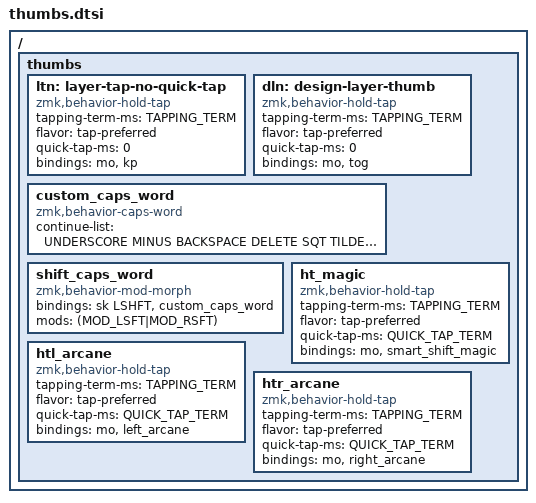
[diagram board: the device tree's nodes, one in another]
/*
*
* Copyright (c) 2022 Rafael Romão
* SPDX-License-Identifier: MIT
*
*/

/ {
    // #define SMART_REPEAT(NAME, LABEL, DEFAULT) \
    //     NAME: NAME { \
    //         compatible = "zmk,behavior-antecedent-morph"; \
    //         label = LABEL; \
    //         #binding-cells = <0>; \
    //         max-delay-ms = <ADAPTIVE_KEY_TIMEOUT>; \
    //         defaults = <DEFAULT>; \
    //         antecedents = < \
    //                        A           B           C           D           E           F           G           H          \
    //                        I           J           K           L           M           N           O           P          \
    //                        Q           R           S           T           U           V           W           X          \
    //                        Y           Z \
    //                        >; \
    //         bindings =    < \
    //                        &kp V       &key_repeat &key_repeat &key_repeat &key_repeat &key_repeat &key_repeat &key_repeat\
    //                        &kp V       &key_repeat &key_repeat &key_repeat &key_repeat &key_repeat &key_repeat &key_repeat\
    //                        &kp V       &key_repeat &key_repeat &key_repeat &key_repeat &key_repeat &key_repeat &key_repeat\
    //                        &key_repeat &key_repeat \
    //                        >; \
    //     };

    #define LEFT_ARCANE(NAME, DEFAULT) \
      NAME: NAME { \
        compatible = "zmk,behavior-antecedent-morph"; \
        #binding-cells = <0>; \
        max-delay-ms = <ADAPTIVE_KEY_TIMEOUT>; \
        defaults = <DEFAULT>; \
        antecedents = < \
                       A     B          C      G          J       M       N       P         W        COMM    \
                       >; \
        bindings =    < \
                       &mc_a &mc_ecause &mc_an &mc_eneral &mc_ust &mc_ent &mc_ion &mc_retty &mc_hich &mc_and \
                       >; \
    };

    #define RIGHT_ARCANE(NAME, DEFAULT) \
      NAME: NAME { \
        compatible = "zmk,behavior-antecedent-morph"; \
        #binding-cells = <0>; \
        max-delay-ms = <ADAPTIVE_KEY_TIMEOUT>; \
        defaults = <DEFAULT>; \
        antecedents = < \
                       A   B          I       Q        X      Y       COMM    SPACE   \
                       >; \
        bindings =    < \
                       &nd &mc_ecause &mc_on  &mc_ueen &mc_ex &mc_eah &mc_but &mc_the \
                       >; \
    };

    #define SMART_MAGIC(NAME, DEFAULT) \
      NAME: NAME { \
        compatible = "zmk,behavior-antecedent-morph"; \
        #binding-cells = <0>; \
        max-delay-ms = <ADAPTIVE_KEY_TIMEOUT>; \
        defaults = <DEFAULT>; \
        antecedents = < \
                       A     C      E      F     G     H     O     P     R     S     T     U     W     Y     \
                       >; \
        bindings =    < \
                       &kp O &kp S  &kp U  &kp Y &kp S &kp Y &kp A &kp H &kp L &kp C &kp M &kp E &kp S &kp P \
                       >; \
    };
    

    thumbs {

        ltn: layer-tap-no-quick-tap {
          compatible = "zmk,behavior-hold-tap";
          #binding-cells = <2>;
          tapping-term-ms = <TAPPING_TERM>;
          flavor = "tap-preferred";
          quick-tap-ms = <0>;
          bindings = <&mo>, <&kp>;
        };

        dln: design-layer-thumb {
          compatible = "zmk,behavior-hold-tap";
          #binding-cells = <2>;
          tapping-term-ms = <TAPPING_TERM>;
          flavor = "tap-preferred";
          quick-tap-ms = <0>;
          bindings = <&mo>, <&tog>;
        };
        
        // ******************* SMART SHIFT / CAPS WORD ******************* //

        custom_caps_word: custom_caps_word {
            compatible = "zmk,behavior-caps-word";
            #binding-cells = <0>;  
            continue-list = <UNDERSCORE MINUS BACKSPACE DELETE SQT TILDE CARET GRAVE >;
        };

        shift_caps_word: shift_caps_word {
            compatible = "zmk,behavior-mod-morph";
            #binding-cells = <0>;
            bindings = <&sk LSHFT>, <&custom_caps_word>;
            mods = <(MOD_LSFT|MOD_RSFT)>;
        };

        // ******************** SMART SHIFT / REPEAT KEY ******************** //

        // SMART_REPEAT(smart_shift_repeat, "smart_shift_repeat", &key_repeat)
        //
        // ht_repeat: ht_repeat {
        //     compatible = "zmk,behavior-hold-tap";
        //     #binding-cells = <2>;
        //     tapping-term-ms = <TAPPING_TERM>;
        //     flavor = "tap-preferred";
        //     quick-tap-ms = <QUICK_TAP_TERM>;
        //     bindings = <&mo>, <&smart_shift_repeat>;
        // };

        // ******************** SMART SHIFT / MAGIC KEY ******************** //

        SMART_MAGIC(smart_shift_magic, &key_repeat)
        LEFT_ARCANE(left_arcane, &key_repeat)
        RIGHT_ARCANE(right_arcane, &key_repeat)
        // SMART_MAGIC(smart_shift_magic, "smart_shift_magic", &shift_caps_word)

        ht_magic: ht_magic {
          compatible = "zmk,behavior-hold-tap";
          #binding-cells = <2>;
          tapping-term-ms = <TAPPING_TERM>;
          flavor = "tap-preferred";
          quick-tap-ms = <QUICK_TAP_TERM>;
          bindings = <&mo>, <&smart_shift_magic>;
        };

        htl_arcane: htl_arcane {
          compatible = "zmk,behavior-hold-tap";
          #binding-cells = <2>;
          tapping-term-ms = <TAPPING_TERM>;
          flavor = "tap-preferred";
          quick-tap-ms = <QUICK_TAP_TERM>;
          bindings = <&mo>, <&left_arcane>;
        };

        htr_arcane: htr_arcane {
          compatible = "zmk,behavior-hold-tap";
          #binding-cells = <2>;
          tapping-term-ms = <TAPPING_TERM>;
          flavor = "tap-preferred";
          quick-tap-ms = <QUICK_TAP_TERM>;
          bindings = <&mo>, <&right_arcane>;
        };


        
    };
};
